# STM32F405-TEST register map
STM32F405 subset for tests
Registers are 32-bit, access not given, reset 0x0 unless marked. A register's access mark holds for its fields unless they carry their own. Offsets are from the block's base; lines under a group give offsets from that group; [hi:lo] are bit positions; {n}, {i} and the like mark numbered series; 'fields as' and 'values as' point back to an identical list; <NAME> marks a mode.

## Memory map
0x2001F000 SCRATCH — RAM-backed registers for write tests
0x40000000 TIM2 size 0x400 — General purpose timer
0x40004400 USART2
0x40011000 USART1 — Universal synchronous asynchronous receiver transmitter

## SCRATCH — RAM-backed registers for write tests
Base 0x2001F000
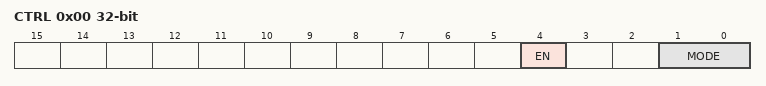
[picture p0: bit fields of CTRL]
0x00 CTRL — Control
  [4] EN — Enable
  [1:0] MODE
    0=Off; 1=Slow; 2=Fast
0x04 VALUE
0x08 STATUS ro — Read-only status

## TIM2 — General purpose timer
Base 0x40000000
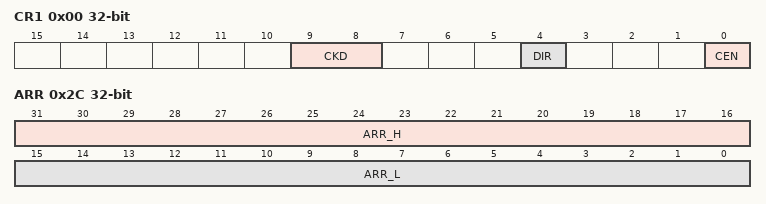
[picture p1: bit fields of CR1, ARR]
0x00 CR1 rw — control register 1
  [9:8] CKD — Clock division
    0=Div1; 1=Div2; 2=Div4
  [4] DIR — Direction
  [0] CEN — Counter enable
0x24 CNT rw — counter
0x28 PSC rw — prescaler
  [15:0] PSC — Prescaler value
0x2C ARR rw — auto-reload register
  [31:16] ARR_H — High auto-reload value
  [15:0] ARR_L — Low auto-reload value

## USART1 — Universal synchronous asynchronous receiver transmitter
Base 0x40011000
Same registers: USART2 0x40004400
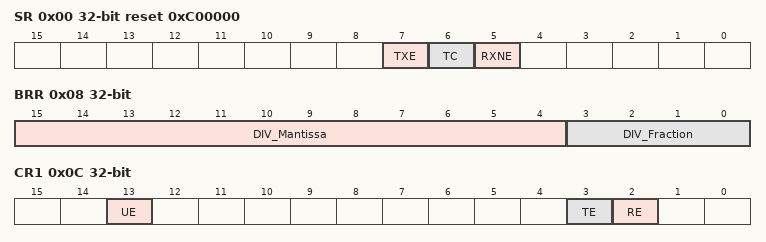
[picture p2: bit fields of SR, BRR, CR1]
0x00 SR reset 0xC00000 — Status register
  [7] TXE ro — Transmit data register empty
  [6] TC — Transmission complete
  [5] RXNE — Read data register not empty
0x04 DR read-modifies — Data register
  [8:0] DR — Data value
0x08 BRR — Baud rate register
  [15:4] DIV_Mantissa — mantissa of USARTDIV
  [3:0] DIV_Fraction — fraction of USARTDIV
0x0C CR1 — Control register 1
  [13] UE — USART enable
  [3] TE — Transmitter enable
  [2] RE — Receiver enable
